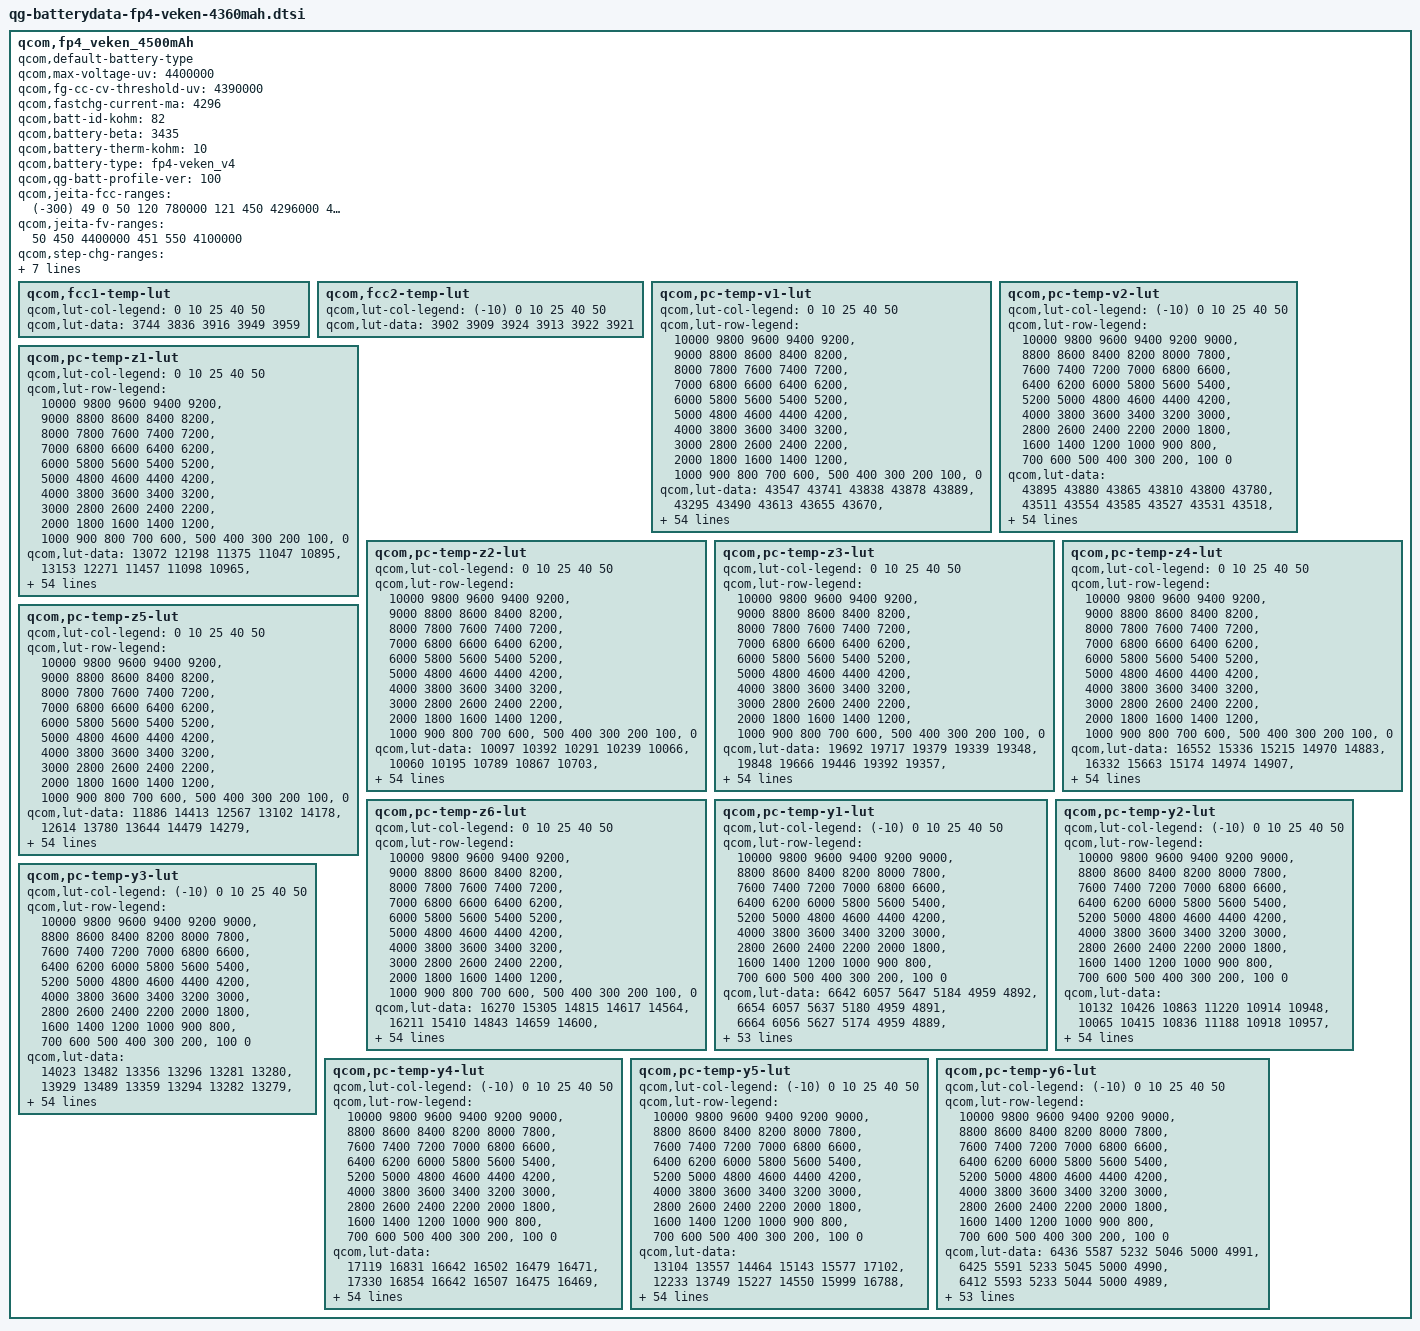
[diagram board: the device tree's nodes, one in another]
/*
 * Copyright (c) 2018, The Linux Foundation. All rights reserved.
 *
 * This program is free software; you can redistribute it and/or modify
 * it under the terms of the GNU General Public License version 2 and
 * only version 2 as published by the Free Software Foundation.
 *
 * This program is distributed in the hope that it will be useful,
 * but WITHOUT ANY WARRANTY; without even the implied warranty of
 * MERCHANTABILITY or FITNESS FOR A PARTICULAR PURPOSE.  See the
 * GNU General Public License for more details.
 */

qcom,fp4_veken_4500mAh {
	/* 4251176_TCL_T1Pro_Veken_4500mAH_PM6150_averaged_MasterSlave_Nov29th2019 */
	qcom,default-battery-type;
	qcom,max-voltage-uv = <4400000>;
	qcom,fg-cc-cv-threshold-uv = <4390000>;
	qcom,fastchg-current-ma = <4296>;//change to 1.1c
	qcom,batt-id-kohm = <82>;
	qcom,battery-beta = <3435>;
	qcom,battery-therm-kohm = <10>;
	qcom,battery-type = "fp4-veken_v4";
	qcom,qg-batt-profile-ver = <100>;

/*zxzadd if change below value  need change the value temperature define in driver
smblib_get_prop_batt_health 
#define JEITA_HARD_COLD_TEMP (0)
#define JEITA_SOFT_COLD_TEMP (100)
#define JEITA_SOFT_HOT_TEMP (450)
#define JEITA_HARD_HOT_TEMP (600)
*/
	qcom,jeita-fcc-ranges = <(-300) 49   0
							50 120   780000
							121 450  4296000
							451 550  1950000
							551 600  0>;

	qcom,jeita-fv-ranges = <50   450   4400000
							451 550   4100000>;

	qcom,step-chg-ranges = <2800000  4250000  4296000
							4250001  4400000  1950000>;

	qcom,ocv-based-step-chg;

/*zxz add comment below value need check */
/*zxz add should notice that below jeitavalue is not work, them is not set in driver, defined 'qcom,sw-jeita-enable' in dtsi ,but smblib_notifier_call
function add "if ((!chg->sw_jeita_enabled)" so not do "jeita_update_work" .
jeita value is set in amss_smxx50/BOOT.XF.3.3/boot_images/QcomPkg/SocPkg/BitraPkg/Settings/Charger/QcomChargerConfig_VbattTh_fp4.cfg

*/
	/* COOL = 10 DegC, WARM = 45 DegC */
	qcom,jeita-soft-thresholds = <0x2aee 0xfb3>;
	/* COLD = 0 DegC, HOT = 60 DegC */
	qcom,jeita-hard-thresholds = <0x3733 0xa2c>;
	/* COOL hys = 13 DegC, WARM hys = 42 DegC */
	qcom,jeita-soft-hys-thresholds = <0x279a 0x1124>;

	qcom,jeita-soft-fcc-ua = <1950000 1950000>;
	qcom,jeita-soft-fv-uv = <4100000 4100000>;


	qcom,fcc1-temp-lut {
		qcom,lut-col-legend = <0 10 25 40 50>;
		qcom,lut-data = <3744 3836 3916 3949 3959>;
	};

	qcom,fcc2-temp-lut {
		qcom,lut-col-legend = <(-10) 0 10 25 40 50>;
		qcom,lut-data = <3902 3909 3924 3913 3922 3921>;
	};

	qcom,pc-temp-v1-lut {
		qcom,lut-col-legend = <0 10 25 40 50>;
		qcom,lut-row-legend = <10000 9800 9600 9400 9200>,
			<9000 8800 8600 8400 8200>,
			<8000 7800 7600 7400 7200>,
			<7000 6800 6600 6400 6200>,
			<6000 5800 5600 5400 5200>,
			<5000 4800 4600 4400 4200>,
			<4000 3800 3600 3400 3200>,
			<3000 2800 2600 2400 2200>,
			<2000 1800 1600 1400 1200>,
			<1000 900 800 700 600>,
			<500 400 300 200 100>,
			<0>;
		qcom,lut-data = <43547 43741 43838 43878 43889>,
			<43295 43490 43613 43655 43670>,
			<43050 43248 43383 43427 43440>,
			<42810 43012 43144 43197 43212>,
			<42578 42778 42901 42964 42985>,
			<42352 42543 42663 42729 42756>,
			<42130 42311 42432 42497 42523>,
			<41913 42086 42202 42264 42288>,
			<41701 41865 41972 42034 42057>,
			<41493 41648 41743 41805 41828>,
			<41290 41432 41520 41578 41602>,
			<41096 41222 41303 41358 41381>,
			<40916 41031 41091 41141 41163>,
			<40725 40857 40889 40934 40953>,
			<40489 40671 40692 40734 40749>,
			<40233 40440 40494 40537 40551>,
			<40030 40197 40287 40336 40358>,
			<39878 40011 40093 40139 40172>,
			<39745 39867 39932 39965 39996>,
			<39614 39729 39790 39817 39837>,
			<39490 39582 39629 39654 39668>,
			<39364 39431 39427 39435 39456>,
			<39234 39250 39214 39196 39226>,
			<39101 38993 39010 39008 39036>,
			<38958 38765 38808 38853 38879>,
			<38791 38651 38665 38724 38742>,
			<38642 38577 38578 38619 38625>,
			<38546 38512 38508 38527 38523>,
			<38474 38452 38432 38437 38428>,
			<38417 38398 38359 38346 38339>,
			<38373 38346 38291 38264 38259>,
			<38337 38296 38226 38192 38185>,
			<38301 38250 38168 38128 38118>,
			<38267 38206 38116 38071 38056>,
			<38236 38165 38070 38021 38002>,
			<38206 38128 38028 37973 37946>,
			<38177 38098 37994 37925 37886>,
			<38138 38061 37957 37876 37822>,
			<38076 37999 37899 37810 37747>,
			<37995 37907 37812 37724 37659>,
			<37898 37807 37713 37626 37559>,
			<37773 37693 37605 37517 37449>,
			<37632 37561 37479 37391 37321>,
			<37474 37401 37318 37231 37161>,
			<37333 37253 37171 37090 37024>,
			<37240 37160 37074 36995 36937>,
			<37217 37136 37052 36970 36914>,
			<37195 37117 37035 36956 36897>,
			<37169 37102 37019 36938 36879>,
			<37122 37068 36985 36895 36827>,
			<36943 36874 36782 36669 36577>,
			<36509 36445 36359 36241 36147>,
			<35943 35888 35803 35679 35583>,
			<35182 35126 35038 34914 34818>,
			<33980 33929 33854 33733 33636>,
			<30000 30000 30000 30000 30000>;
	};

	qcom,pc-temp-v2-lut {
		qcom,lut-col-legend = <(-10) 0 10 25 40 50>;
		qcom,lut-row-legend = <10000 9800 9600 9400 9200 9000>,
			<8800 8600 8400 8200 8000 7800>,
			<7600 7400 7200 7000 6800 6600>,
			<6400 6200 6000 5800 5600 5400>,
			<5200 5000 4800 4600 4400 4200>,
			<4000 3800 3600 3400 3200 3000>,
			<2800 2600 2400 2200 2000 1800>,
			<1600 1400 1200 1000 900 800>,
			<700 600 500 400 300 200>,
			<100 0>;
		qcom,lut-data = <43895 43880 43865 43810 43800 43780>,
			<43511 43554 43585 43527 43531 43518>,
			<43163 43251 43318 43260 43272 43264>,
			<42853 42975 43063 43007 43025 43020>,
			<42574 42725 42822 42771 42790 42786>,
			<42328 42484 42585 42539 42558 42555>,
			<42128 42243 42348 42306 42325 42322>,
			<41947 42007 42113 42075 42093 42091>,
			<41721 41776 41885 41847 41865 41864>,
			<41415 41548 41660 41623 41639 41640>,
			<41171 41332 41442 41401 41416 41418>,
			<41071 41140 41229 41184 41196 41200>,
			<41004 40961 41022 40969 40980 40984>,
			<40846 40769 40819 40763 40774 40778>,
			<40354 40568 40619 40562 40576 40576>,
			<39851 40346 40417 40366 40383 40381>,
			<39605 40059 40208 40166 40187 40193>,
			<39428 39735 39994 39968 39994 40012>,
			<39255 39498 39777 39793 39818 39838>,
			<39085 39340 39552 39647 39666 39679>,
			<38919 39196 39337 39492 39504 39509>,
			<38743 39029 39141 39274 39288 39291>,
			<38565 38856 38960 39017 39044 39049>,
			<38430 38702 38801 38817 38850 38857>,
			<38335 38570 38661 38668 38698 38706>,
			<38258 38445 38535 38543 38568 38577>,
			<38188 38310 38421 38434 38455 38463>,
			<38126 38172 38318 38338 38355 38362>,
			<38069 38076 38224 38248 38264 38268>,
			<38014 38014 38139 38161 38180 38180>,
			<37963 37966 38059 38082 38104 38101>,
			<37914 37923 37979 38011 38035 38030>,
			<37867 37886 37904 37948 37972 37966>,
			<37818 37850 37846 37888 37907 37898>,
			<37767 37816 37805 37834 37841 37826>,
			<37713 37780 37768 37779 37770 37747>,
			<37655 37733 37729 37718 37683 37648>,
			<37593 37673 37689 37651 37581 37532>,
			<37525 37607 37640 37580 37490 37430>,
			<37450 37537 37574 37507 37413 37349>,
			<37370 37459 37494 37428 37336 37269>,
			<37287 37365 37393 37333 37241 37174>,
			<37199 37249 37267 37217 37130 37065>,
			<37116 37120 37124 37079 36995 36930>,
			<37037 36983 36991 36952 36881 36817>,
			<36946 36880 36911 36895 36832 36773>,
			<36895 36845 36888 36881 36820 36764>,
			<36841 36810 36867 36864 36804 36748>,
			<36776 36769 36837 36843 36783 36724>,
			<36688 36698 36776 36790 36718 36649>,
			<36506 36521 36579 36592 36485 36381>,
			<36138 36111 36133 36140 36015 35908>,
			<35550 35513 35515 35555 35413 35297>,
			<34710 34679 34667 34771 34602 34476>,
			<33331 33366 33473 33598 33431 33279>,
			<30369 29555 29368 29464 29626 29624>;
	};

	qcom,pc-temp-z1-lut {
		qcom,lut-col-legend = <0 10 25 40 50>;
		qcom,lut-row-legend = <10000 9800 9600 9400 9200>,
			<9000 8800 8600 8400 8200>,
			<8000 7800 7600 7400 7200>,
			<7000 6800 6600 6400 6200>,
			<6000 5800 5600 5400 5200>,
			<5000 4800 4600 4400 4200>,
			<4000 3800 3600 3400 3200>,
			<3000 2800 2600 2400 2200>,
			<2000 1800 1600 1400 1200>,
			<1000 900 800 700 600>,
			<500 400 300 200 100>,
			<0>;
		qcom,lut-data = <13072 12198 11375 11047 10895>,
			<13153 12271 11457 11098 10965>,
			<13199 12267 11500 11129 11004>,
			<13200 12251 11497 11134 11014>,
			<13156 12242 11488 11131 11016>,
			<13116 12236 11479 11129 11017>,
			<13112 12229 11469 11127 11017>,
			<13110 12216 11460 11126 11017>,
			<13107 12194 11456 11124 11017>,
			<13083 12184 11453 11122 11016>,
			<13053 12183 11452 11121 11014>,
			<13041 12183 11452 11120 11014>,
			<13034 12174 11452 11120 11014>,
			<13027 12141 11449 11120 11013>,
			<13009 12115 11445 11118 11012>,
			<12977 12105 11442 11116 11011>,
			<12946 12097 11439 11116 11012>,
			<12910 12096 11438 11117 11013>,
			<12882 12096 11439 11117 11015>,
			<12884 12098 11443 11117 11016>,
			<12902 12108 11447 11117 11018>,
			<12915 12124 11451 11118 11018>,
			<12914 12130 11455 11119 11018>,
			<12911 12123 11460 11121 11018>,
			<12915 12117 11465 11124 11021>,
			<12932 12120 11471 11128 11025>,
			<12949 12129 11478 11132 11027>,
			<12952 12137 11485 11136 11028>,
			<12947 12148 11491 11140 11031>,
			<12944 12158 11496 11145 11034>,
			<12943 12161 11501 11149 11037>,
			<12942 12162 11506 11152 11040>,
			<12943 12162 11511 11154 11044>,
			<12948 12165 11516 11158 11047>,
			<12954 12168 11522 11163 11049>,
			<12964 12175 11529 11167 11052>,
			<12980 12192 11537 11171 11055>,
			<12996 12207 11546 11175 11059>,
			<13016 12215 11552 11179 11061>,
			<13036 12224 11557 11183 11063>,
			<13040 12228 11562 11186 11065>,
			<13028 12234 11571 11188 11068>,
			<13030 12240 11578 11191 11070>,
			<13040 12251 11581 11194 11072>,
			<13065 12253 11590 11198 11072>,
			<13039 12240 11598 11200 11073>,
			<13034 12238 11600 11199 11075>,
			<13039 12234 11597 11200 11074>,
			<13022 12240 11604 11201 11075>,
			<13058 12240 11608 11205 11078>,
			<13080 12259 11613 11210 11080>,
			<13051 12280 11628 11214 11085>,
			<13103 12296 11638 11224 11094>,
			<13106 12313 11652 11236 11106>,
			<13106 12313 11652 11236 11106>,
			<13106 12313 11652 11236 11106>;
	};

	qcom,pc-temp-z2-lut {
		qcom,lut-col-legend = <0 10 25 40 50>;
		qcom,lut-row-legend = <10000 9800 9600 9400 9200>,
			<9000 8800 8600 8400 8200>,
			<8000 7800 7600 7400 7200>,
			<7000 6800 6600 6400 6200>,
			<6000 5800 5600 5400 5200>,
			<5000 4800 4600 4400 4200>,
			<4000 3800 3600 3400 3200>,
			<3000 2800 2600 2400 2200>,
			<2000 1800 1600 1400 1200>,
			<1000 900 800 700 600>,
			<500 400 300 200 100>,
			<0>;
		qcom,lut-data = <10097 10392 10291 10239 10066>,
			<10060 10195 10789 10867 10703>,
			<10032 10156 10993 11172 11141>,
			<10016 10132 10785 11184 11217>,
			<10005 10110 10405 11047 11107>,
			<9999 10087 10313 10871 10946>,
			<9998 10069 10406 10607 10682>,
			<9997 10060 10481 10354 10369>,
			<9996 10054 10423 10377 10346>,
			<9987 10052 10311 10646 10685>,
			<9977 10057 10284 10806 10939>,
			<9976 10067 10293 10793 10930>,
			<9980 10098 10309 10772 10906>,
			<9983 10181 10389 10773 10897>,
			<9971 10231 10533 10794 10913>,
			<9946 10213 10578 10818 10920>,
			<9939 10184 10557 10839 10908>,
			<9973 10182 10524 10851 10895>,
			<10016 10199 10468 10782 10832>,
			<10032 10216 10392 10474 10500>,
			<10040 10226 10383 10302 10279>,
			<10048 10234 10437 10453 10430>,
			<10058 10236 10485 10672 10674>,
			<10069 10225 10467 10674 10711>,
			<10080 10214 10402 10441 10525>,
			<10091 10217 10374 10283 10380>,
			<10102 10230 10387 10315 10504>,
			<10111 10243 10409 10379 10737>,
			<10121 10254 10431 10436 10773>,
			<10129 10265 10457 10501 10600>,
			<10137 10271 10467 10535 10412>,
			<10145 10275 10453 10486 10284>,
			<10154 10279 10433 10407 10182>,
			<10164 10282 10422 10390 10164>,
			<10175 10286 10413 10398 10184>,
			<10185 10290 10409 10410 10215>,
			<10196 10294 10416 10440 10266>,
			<10207 10300 10431 10489 10333>,
			<10222 10314 10452 10528 10383>,
			<10238 10334 10491 10567 10426>,
			<10255 10346 10517 10587 10451>,
			<10274 10350 10525 10584 10446>,
			<10302 10358 10531 10579 10433>,
			<10357 10391 10537 10562 10430>,
			<10714 10601 10605 10535 10428>,
			<10699 10659 10640 10492 10378>,
			<10620 10695 10622 10489 10401>,
			<10531 10734 10628 10493 10409>,
			<10481 10965 10616 10471 10415>,
			<10489 11224 10672 10555 10543>,
			<10478 10796 10786 10624 10393>,
			<10367 10862 10768 10373 10166>,
			<10160 10888 10917 10329 10109>,
			<10013 10741 10891 10265 10072>,
			<10013 10741 10891 10265 10072>,
			<10013 10741 10891 10265 10072>;
	};

	qcom,pc-temp-z3-lut {
		qcom,lut-col-legend = <0 10 25 40 50>;
		qcom,lut-row-legend = <10000 9800 9600 9400 9200>,
			<9000 8800 8600 8400 8200>,
			<8000 7800 7600 7400 7200>,
			<7000 6800 6600 6400 6200>,
			<6000 5800 5600 5400 5200>,
			<5000 4800 4600 4400 4200>,
			<4000 3800 3600 3400 3200>,
			<3000 2800 2600 2400 2200>,
			<2000 1800 1600 1400 1200>,
			<1000 900 800 700 600>,
			<500 400 300 200 100>,
			<0>;
		qcom,lut-data = <19692 19717 19379 19339 19348>,
			<19848 19666 19446 19392 19357>,
			<19960 19698 19494 19422 19393>,
			<19998 19730 19519 19447 19415>,
			<20015 19742 19538 19470 19432>,
			<20022 19744 19550 19481 19441>,
			<20017 19744 19559 19465 19434>,
			<20003 19741 19562 19442 19420>,
			<19995 19731 19548 19438 19417>,
			<19994 19724 19522 19448 19427>,
			<19992 19716 19505 19453 19433>,
			<19983 19707 19490 19445 19428>,
			<19959 19700 19480 19435 19417>,
			<19942 19680 19486 19429 19410>,
			<19963 19668 19500 19425 19405>,
			<20005 19662 19504 19421 19399>,
			<20017 19651 19497 19417 19393>,
			<19975 19642 19487 19414 19384>,
			<19925 19630 19473 19404 19374>,
			<19909 19621 19454 19381 19359>,
			<19902 19623 19449 19367 19349>,
			<19898 19630 19464 19380 19357>,
			<19897 19638 19481 19401 19371>,
			<19896 19653 19479 19401 19372>,
			<19896 19665 19470 19374 19346>,
			<19903 19662 19460 19354 19327>,
			<19909 19651 19447 19352 19348>,
			<19907 19641 19437 19351 19389>,
			<19897 19633 19439 19358 19401>,
			<19885 19626 19448 19394 19403>,
			<19871 19625 19458 19418 19403>,
			<19856 19626 19471 19417 19398>,
			<19844 19626 19482 19415 19387>,
			<19832 19628 19483 19411 19378>,
			<19821 19630 19480 19403 19370>,
			<19810 19629 19476 19394 19364>,
			<19798 19622 19469 19387 19361>,
			<19789 19615 19460 19381 19359>,
			<19783 19612 19455 19377 19357>,
			<19777 19609 19452 19374 19355>,
			<19768 19605 19448 19372 19354>,
			<19754 19597 19444 19371 19356>,
			<19735 19586 19440 19371 19359>,
			<19702 19570 19433 19369 19360>,
			<19564 19516 19417 19360 19358>,
			<19491 19495 19412 19356 19349>,
			<19391 19477 19402 19352 19336>,
			<19331 19456 19401 19343 19335>,
			<19326 19385 19393 19343 19329>,
			<19323 19329 19371 19335 19323>,
			<19322 19453 19372 19332 19344>,
			<19330 19427 19363 19359 19359>,
			<19335 19329 19330 19360 19365>,
			<19340 19314 19322 19355 19361>,
			<19340 19314 19322 19355 19361>,
			<19340 19314 19322 19355 19361>;
	};

	qcom,pc-temp-z4-lut {
		qcom,lut-col-legend = <0 10 25 40 50>;
		qcom,lut-row-legend = <10000 9800 9600 9400 9200>,
			<9000 8800 8600 8400 8200>,
			<8000 7800 7600 7400 7200>,
			<7000 6800 6600 6400 6200>,
			<6000 5800 5600 5400 5200>,
			<5000 4800 4600 4400 4200>,
			<4000 3800 3600 3400 3200>,
			<3000 2800 2600 2400 2200>,
			<2000 1800 1600 1400 1200>,
			<1000 900 800 700 600>,
			<500 400 300 200 100>,
			<0>;
		qcom,lut-data = <16552 15336 15215 14970 14883>,
			<16332 15663 15174 14974 14907>,
			<16126 15572 15126 14943 14882>,
			<15932 15376 15066 14904 14855>,
			<15743 15232 14998 14849 14817>,
			<15582 15136 14936 14813 14787>,
			<15463 15059 14871 14803 14776>,
			<15366 15000 14828 14795 14766>,
			<15284 14953 14814 14782 14756>,
			<15213 14917 14804 14749 14727>,
			<15152 14889 14797 14727 14705>,
			<15102 14865 14793 14722 14702>,
			<15059 14838 14787 14717 14699>,
			<15021 14802 14765 14710 14695>,
			<14985 14784 14728 14699 14688>,
			<14952 14802 14714 14689 14682>,
			<14929 14829 14711 14683 14679>,
			<14913 14831 14709 14677 14677>,
			<14899 14804 14705 14676 14675>,
			<14878 14776 14701 14685 14680>,
			<14849 14764 14705 14698 14690>,
			<14830 14755 14724 14724 14713>,
			<14823 14759 14755 14766 14756>,
			<14819 14837 14803 14809 14796>,
			<14822 14915 14873 14858 14842>,
			<14858 14918 14899 14883 14868>,
			<14892 14908 14892 14876 14839>,
			<14895 14896 14879 14859 14779>,
			<14894 14881 14861 14831 14744>,
			<14893 14864 14833 14778 14724>,
			<14884 14847 14805 14737 14712>,
			<14868 14828 14775 14720 14705>,
			<14855 14810 14750 14709 14701>,
			<14843 14794 14739 14706 14698>,
			<14831 14780 14732 14705 14696>,
			<14820 14769 14730 14704 14694>,
			<14810 14761 14729 14707 14697>,
			<14801 14757 14729 14713 14704>,
			<14790 14758 14732 14720 14711>,
			<14783 14761 14745 14733 14723>,
			<14782 14761 14752 14741 14729>,
			<14783 14754 14742 14732 14719>,
			<14782 14748 14732 14723 14708>,
			<14776 14744 14731 14725 14710>,
			<14774 14720 14716 14718 14700>,
			<14833 14712 14697 14700 14689>,
			<14938 14718 14694 14694 14689>,
			<14997 14732 14677 14681 14671>,
			<14996 14799 14669 14658 14652>,
			<14990 14855 14687 14659 14647>,
			<14987 14723 14709 14696 14665>,
			<15004 14767 14735 14680 14660>,
			<15009 14883 14772 14679 14655>,
			<15018 14903 14783 14687 14661>,
			<15018 14903 14783 14687 14661>,
			<15018 14903 14783 14687 14661>;
	};

	qcom,pc-temp-z5-lut {
		qcom,lut-col-legend = <0 10 25 40 50>;
		qcom,lut-row-legend = <10000 9800 9600 9400 9200>,
			<9000 8800 8600 8400 8200>,
			<8000 7800 7600 7400 7200>,
			<7000 6800 6600 6400 6200>,
			<6000 5800 5600 5400 5200>,
			<5000 4800 4600 4400 4200>,
			<4000 3800 3600 3400 3200>,
			<3000 2800 2600 2400 2200>,
			<2000 1800 1600 1400 1200>,
			<1000 900 800 700 600>,
			<500 400 300 200 100>,
			<0>;
		qcom,lut-data = <11886 14413 12567 13102 14178>,
			<12614 13780 13644 14479 14279>,
			<13204 14265 14624 15634 16088>,
			<13607 14843 15494 16974 17343>,
			<13900 15368 16345 18793 18701>,
			<14135 15882 17208 19693 19560>,
			<14338 16345 18357 18973 19423>,
			<14529 16749 19093 17953 19227>,
			<14759 17188 19044 18480 19855>,
			<15214 17541 18856 21544 23476>,
			<15659 18062 18677 23352 26139>,
			<15766 18631 18349 23071 25691>,
			<15786 19177 18101 22663 24784>,
			<15818 20344 19895 22874 24720>,
			<17557 20981 23876 24323 26144>,
			<21016 20322 25137 25835 27203>,
			<22203 19430 24533 27136 26780>,
			<21184 19541 23684 28285 25703>,
			<20069 20118 23016 27744 24271>,
			<20255 21038 22919 23542 21923>,
			<21764 23532 24295 21313 20779>,
			<23804 28090 32731 26724 23517>,
			<26533 32520 41002 34677 27989>,
			<30194 37714 39409 34519 28103>,
			<34261 41364 32041 24669 20795>,
			<39901 39609 26133 17194 15196>,
			<43976 33334 22016 15796 15983>,
			<43531 28780 19356 15011 17918>,
			<40937 26400 19188 15359 19582>,
			<38199 24888 19413 18225 21177>,
			<35616 24801 19831 21410 22344>,
			<33158 25294 22413 23899 22861>,
			<31585 26003 26202 26110 23226>,
			<30517 27885 29171 27448 23749>,
			<29680 30346 32046 28444 24523>,
			<28861 31082 33178 28875 25138>,
			<28088 31087 32459 28333 25470>,
			<27851 31026 31138 27139 25695>,
			<29032 31420 29725 25716 25308>,
			<30503 32217 27880 23446 22685>,
			<30384 32267 26244 21667 20847>,
			<28748 30519 25091 20970 20928>,
			<27814 28564 24014 20404 21047>,
			<26873 26828 22620 19641 20984>,
			<22035 27109 23042 18982 20817>,
			<18173 25404 24156 18997 19077>,
			<13919 21365 21787 18653 17041>,
			<12110 19251 22544 18066 18007>,
			<12039 15544 21621 20382 19528>,
			<12053 12864 17589 19192 19704>,
			<12124 19269 16872 15338 18983>,
			<12051 15940 14845 16984 19612>,
			<11973 12316 12947 16550 20090>,
			<11867 11920 12520 15346 17888>,
			<11867 11920 12520 15346 17888>,
			<11867 11920 12520 15346 17888>;
	};

	qcom,pc-temp-z6-lut {
		qcom,lut-col-legend = <0 10 25 40 50>;
		qcom,lut-row-legend = <10000 9800 9600 9400 9200>,
			<9000 8800 8600 8400 8200>,
			<8000 7800 7600 7400 7200>,
			<7000 6800 6600 6400 6200>,
			<6000 5800 5600 5400 5200>,
			<5000 4800 4600 4400 4200>,
			<4000 3800 3600 3400 3200>,
			<3000 2800 2600 2400 2200>,
			<2000 1800 1600 1400 1200>,
			<1000 900 800 700 600>,
			<500 400 300 200 100>,
			<0>;
		qcom,lut-data = <16270 15305 14815 14617 14564>,
			<16211 15410 14843 14659 14600>,
			<16142 15378 14853 14670 14613>,
			<16062 15296 14844 14670 14615>,
			<15962 15229 14819 14661 14609>,
			<15866 15178 14796 14649 14600>,
			<15791 15134 14775 14635 14591>,
			<15725 15097 14755 14621 14580>,
			<15672 15065 14736 14610 14571>,
			<15630 15040 14719 14602 14565>,
			<15592 15022 14706 14595 14560>,
			<15549 15006 14697 14588 14554>,
			<15498 14982 14689 14581 14548>,
			<15463 14950 14681 14574 14542>,
			<15451 14934 14674 14566 14535>,
			<15445 14935 14667 14559 14529>,
			<15432 14937 14661 14554 14523>,
			<15399 14934 14655 14550 14518>,
			<15364 14915 14647 14544 14513>,
			<15345 14900 14636 14536 14507>,
			<15331 14900 14633 14531 14503>,
			<15324 14901 14649 14549 14517>,
			<15324 14905 14673 14581 14545>,
			<15323 14948 14695 14596 14559>,
			<15326 14989 14719 14603 14566>,
			<15347 14990 14728 14606 14569>,
			<15367 14982 14720 14602 14567>,
			<15367 14974 14710 14595 14563>,
			<15364 14965 14703 14589 14558>,
			<15359 14956 14697 14585 14552>,
			<15349 14948 14692 14581 14546>,
			<15337 14942 14687 14575 14540>,
			<15327 14937 14683 14569 14533>,
			<15318 14933 14680 14564 14528>,
			<15311 14930 14676 14560 14522>,
			<15303 14927 14674 14556 14519>,
			<15297 14923 14670 14555 14519>,
			<15294 14920 14667 14554 14520>,
			<15295 14923 14668 14554 14521>,
			<15296 14927 14673 14558 14525>,
			<15297 14929 14675 14561 14528>,
			<15299 14926 14671 14557 14525>,
			<15299 14923 14665 14554 14522>,
			<15291 14917 14663 14554 14523>,
			<15236 14888 14650 14547 14518>,
			<15224 14877 14641 14537 14508>,
			<15217 14870 14635 14532 14503>,
			<15212 14866 14627 14522 14493>,
			<15211 14860 14620 14512 14482>,
			<15213 14859 14618 14508 14476>,
			<15220 14871 14630 14524 14497>,
			<15239 14883 14640 14533 14505>,
			<15255 14891 14642 14536 14508>,
			<15282 14904 14647 14540 14512>,
			<15282 14904 14647 14540 14512>,
			<15282 14904 14647 14540 14512>;
	};

	qcom,pc-temp-y1-lut {
		qcom,lut-col-legend = <(-10) 0 10 25 40 50>;
		qcom,lut-row-legend = <10000 9800 9600 9400 9200 9000>,
			<8800 8600 8400 8200 8000 7800>,
			<7600 7400 7200 7000 6800 6600>,
			<6400 6200 6000 5800 5600 5400>,
			<5200 5000 4800 4600 4400 4200>,
			<4000 3800 3600 3400 3200 3000>,
			<2800 2600 2400 2200 2000 1800>,
			<1600 1400 1200 1000 900 800>,
			<700 600 500 400 300 200>,
			<100 0>;
		qcom,lut-data = <6642 6057 5647 5184 4959 4892>,
			<6654 6057 5637 5180 4959 4891>,
			<6664 6056 5627 5174 4959 4889>,
			<6673 6053 5616 5168 4957 4887>,
			<6680 6051 5608 5163 4956 4886>,
			<6684 6050 5601 5160 4954 4885>,
			<6676 6050 5596 5159 4952 4884>,
			<6661 6049 5592 5158 4950 4884>,
			<6656 6048 5586 5156 4948 4883>,
			<6652 6041 5577 5153 4945 4882>,
			<6650 6034 5571 5149 4944 4881>,
			<6665 6024 5568 5147 4944 4880>,
			<6695 6013 5566 5146 4944 4879>,
			<6702 6012 5562 5145 4944 4879>,
			<6688 6029 5556 5145 4941 4879>,
			<6676 6044 5552 5144 4939 4879>,
			<6680 6046 5556 5145 4941 4879>,
			<6691 6047 5564 5145 4943 4880>,
			<6695 6049 5567 5146 4944 4879>,
			<6694 6051 5565 5148 4943 4878>,
			<6693 6052 5563 5150 4943 4877>,
			<6689 6051 5561 5152 4943 4878>,
			<6679 6046 5559 5154 4945 4880>,
			<6668 6043 5560 5156 4946 4882>,
			<6652 6048 5569 5161 4948 4883>,
			<6639 6052 5577 5166 4951 4883>,
			<6636 6048 5577 5170 4953 4885>,
			<6639 6037 5577 5174 4955 4888>,
			<6638 6033 5578 5178 4957 4890>,
			<6630 6035 5585 5182 4960 4891>,
			<6621 6038 5590 5187 4962 4893>,
			<6617 6035 5589 5192 4965 4895>,
			<6615 6029 5584 5198 4968 4898>,
			<6613 6028 5584 5203 4971 4900>,
			<6614 6033 5587 5208 4976 4901>,
			<6614 6039 5590 5212 4980 4903>,
			<6608 6038 5590 5214 4981 4904>,
			<6593 6037 5590 5217 4981 4907>,
			<6584 6035 5593 5219 4982 4908>,
			<6593 6027 5607 5222 4983 4909>,
			<6607 6017 5620 5225 4984 4910>,
			<6610 6012 5623 5229 4985 4911>,
			<6608 6005 5621 5233 4986 4911>,
			<6596 5999 5621 5239 4988 4912>,
			<6565 5999 5625 5248 4992 4914>,
			<6605 6021 5632 5253 4996 4917>,
			<6605 6033 5628 5252 4996 4919>,
			<6619 6044 5644 5251 4996 4919>,
			<6619 6049 5641 5257 4996 4918>,
			<6595 6023 5643 5254 4997 4918>,
			<6619 6016 5641 5266 4996 4919>,
			<6652 6020 5649 5267 5001 4922>,
			<6670 6044 5660 5281 5007 4926>,
			<6745 6053 5663 5299 5015 4934>,
			<6745 6053 5663 5299 5015 4934>,
			<6745 6053 5663 5299 5015 4934>;
	};

	qcom,pc-temp-y2-lut {
		qcom,lut-col-legend = <(-10) 0 10 25 40 50>;
		qcom,lut-row-legend = <10000 9800 9600 9400 9200 9000>,
			<8800 8600 8400 8200 8000 7800>,
			<7600 7400 7200 7000 6800 6600>,
			<6400 6200 6000 5800 5600 5400>,
			<5200 5000 4800 4600 4400 4200>,
			<4000 3800 3600 3400 3200 3000>,
			<2800 2600 2400 2200 2000 1800>,
			<1600 1400 1200 1000 900 800>,
			<700 600 500 400 300 200>,
			<100 0>;
		qcom,lut-data = <10132 10426 10863 11220 10914 10948>,
			<10065 10415 10836 11188 10918 10957>,
			<10035 10412 10808 11137 10916 10958>,
			<10034 10413 10780 11080 10911 10955>,
			<10053 10419 10757 11030 10902 10947>,
			<10083 10426 10741 11001 10891 10937>,
			<10138 10440 10729 10987 10869 10906>,
			<10219 10457 10721 10974 10844 10855>,
			<10285 10457 10720 10975 10848 10816>,
			<10348 10433 10722 10979 10912 10779>,
			<10387 10414 10724 10982 10959 10760>,
			<10390 10514 10725 10975 10935 10781>,
			<10385 10707 10727 10961 10890 10820>,
			<10406 10756 10740 10959 10880 10825>,
			<10547 10713 10812 10971 10902 10795>,
			<10666 10677 10876 10992 10933 10771>,
			<10427 10687 10896 11040 10964 10825>,
			<9874 10718 10908 11117 11004 10946>,
			<9680 10749 10918 11170 11064 11029>,
			<9676 10783 10928 11210 11186 11092>,
			<9674 10819 10939 11233 11271 11126>,
			<9671 10862 10959 11210 11231 11118>,
			<9669 10907 10989 11155 11142 11096>,
			<9667 10922 11017 11138 11102 11081>,
			<9666 10917 11043 11163 11086 11059>,
			<9665 10913 11068 11196 11079 11046>,
			<9664 10935 11094 11221 11102 11064>,
			<9663 10989 11118 11244 11165 11104>,
			<9662 11009 11125 11266 11220 11135>,
			<9661 10985 11125 11287 11265 11165>,
			<9661 10949 11125 11305 11309 11192>,
			<9660 10916 11131 11319 11360 11215>,
			<9659 10877 11144 11334 11413 11243>,
			<9659 10835 11147 11340 11440 11268>,
			<9658 10799 11125 11333 11430 11304>,
			<9658 10749 11096 11321 11400 11333>,
			<9658 10529 11074 11310 11335 11305>,
			<9658 9982 11053 11291 11225 11212>,
			<9657 9704 11028 11275 11179 11170>,
			<9657 9689 10997 11264 11187 11152>,
			<9657 9680 10960 11251 11202 11128>,
			<9656 9673 10915 11228 11195 11112>,
			<9656 9667 10863 11194 11166 11101>,
			<9656 9664 10807 11176 11137 11085>,
			<9656 9662 10737 11153 11087 11025>,
			<9656 9660 10662 11060 11044 10878>,
			<9656 9660 10652 11077 11021 10822>,
			<9655 9659 10623 11069 10993 10835>,
			<9655 9658 10591 11075 11004 10850>,
			<9655 9657 10575 11052 11010 10876>,
			<9654 9656 10516 11046 10971 10829>,
			<9654 9656 10433 10998 10904 10745>,
			<9652 9654 10343 10919 10826 10684>,
			<9650 9653 10081 10860 10774 10611>,
			<9650 9653 10081 10860 10774 10611>,
			<9650 9653 10081 10860 10774 10611>;
	};

	qcom,pc-temp-y3-lut {
		qcom,lut-col-legend = <(-10) 0 10 25 40 50>;
		qcom,lut-row-legend = <10000 9800 9600 9400 9200 9000>,
			<8800 8600 8400 8200 8000 7800>,
			<7600 7400 7200 7000 6800 6600>,
			<6400 6200 6000 5800 5600 5400>,
			<5200 5000 4800 4600 4400 4200>,
			<4000 3800 3600 3400 3200 3000>,
			<2800 2600 2400 2200 2000 1800>,
			<1600 1400 1200 1000 900 800>,
			<700 600 500 400 300 200>,
			<100 0>;
		qcom,lut-data = <14023 13482 13356 13296 13281 13280>,
			<13929 13489 13359 13294 13282 13279>,
			<13869 13495 13362 13293 13283 13278>,
			<13836 13499 13365 13293 13284 13278>,
			<13822 13502 13368 13294 13285 13278>,
			<13819 13503 13370 13295 13286 13278>,
			<13845 13501 13370 13297 13288 13279>,
			<13891 13498 13370 13300 13289 13280>,
			<13877 13499 13370 13302 13290 13281>,
			<13690 13515 13372 13306 13291 13285>,
			<13543 13527 13373 13308 13291 13288>,
			<13558 13505 13372 13308 13291 13289>,
			<13595 13463 13371 13307 13292 13290>,
			<13604 13451 13370 13308 13292 13290>,
			<13589 13457 13370 13312 13297 13290>,
			<13567 13461 13370 13316 13301 13290>,
			<13541 13456 13370 13314 13299 13291>,
			<13512 13442 13371 13310 13295 13294>,
			<13504 13433 13370 13309 13294 13295>,
			<13510 13428 13364 13313 13296 13295>,
			<13516 13423 13357 13317 13297 13295>,
			<13508 13415 13352 13314 13295 13291>,
			<13486 13404 13348 13306 13289 13282>,
			<13477 13396 13344 13300 13285 13280>,
			<13483 13390 13341 13297 13283 13280>,
			<13494 13383 13338 13294 13282 13280>,
			<13510 13370 13336 13296 13282 13280>,
			<13535 13351 13334 13298 13282 13281>,
			<13561 13343 13334 13299 13282 13281>,
			<13588 13343 13333 13298 13282 13279>,
			<13618 13345 13333 13297 13283 13278>,
			<13654 13350 13331 13297 13283 13278>,
			<13698 13359 13329 13299 13284 13279>,
			<13742 13368 13328 13299 13285 13279>,
			<13782 13373 13330 13300 13285 13280>,
			<13823 13379 13333 13300 13285 13280>,
			<13866 13387 13335 13300 13284 13280>,
			<13913 13396 13338 13299 13282 13278>,
			<13963 13407 13340 13298 13281 13278>,
			<14018 13421 13343 13297 13281 13278>,
			<14074 13439 13344 13297 13282 13279>,
			<14124 13462 13343 13298 13282 13281>,
			<14168 13493 13341 13298 13283 13282>,
			<14222 13537 13342 13298 13283 13280>,
			<14289 13600 13346 13299 13282 13277>,
			<14361 13667 13347 13305 13287 13283>,
			<14301 13653 13348 13305 13288 13288>,
			<14362 13714 13355 13305 13293 13290>,
			<14443 13786 13364 13314 13299 13293>,
			<14546 13863 13373 13320 13300 13293>,
			<14653 13942 13376 13314 13295 13289>,
			<14795 14061 13379 13310 13293 13290>,
			<15283 14266 13392 13321 13296 13292>,
			<16203 14597 13423 13330 13303 13297>,
			<16203 14597 13423 13330 13303 13297>,
			<16203 14597 13423 13330 13303 13297>;
	};

	qcom,pc-temp-y4-lut {
		qcom,lut-col-legend = <(-10) 0 10 25 40 50>;
		qcom,lut-row-legend = <10000 9800 9600 9400 9200 9000>,
			<8800 8600 8400 8200 8000 7800>,
			<7600 7400 7200 7000 6800 6600>,
			<6400 6200 6000 5800 5600 5400>,
			<5200 5000 4800 4600 4400 4200>,
			<4000 3800 3600 3400 3200 3000>,
			<2800 2600 2400 2200 2000 1800>,
			<1600 1400 1200 1000 900 800>,
			<700 600 500 400 300 200>,
			<100 0>;
		qcom,lut-data = <17119 16831 16642 16502 16479 16471>,
			<17330 16854 16642 16507 16475 16469>,
			<17459 16885 16642 16511 16472 16468>,
			<17527 16918 16644 16514 16471 16468>,
			<17552 16946 16645 16517 16470 16468>,
			<17556 16961 16647 16519 16470 16468>,
			<17488 16967 16648 16521 16472 16470>,
			<17367 16970 16650 16522 16474 16472>,
			<17374 16967 16654 16523 16477 16472>,
			<17656 16939 16664 16528 16481 16472>,
			<17900 16918 16677 16534 16486 16472>,
			<17945 17011 16689 16542 16493 16474>,
			<17972 17189 16704 16555 16502 16479>,
			<17930 17238 16734 16568 16508 16485>,
			<17476 17225 16806 16581 16511 16494>,
			<17080 17202 16856 16597 16515 16503>,
			<17109 17093 16853 16618 16526 16509>,
			<17208 16899 16840 16643 16546 16515>,
			<17237 16836 16816 16665 16567 16525>,
			<17166 16834 16739 16688 16597 16550>,
			<17072 16833 16663 16702 16616 16568>,
			<17000 16817 16623 16659 16590 16551>,
			<16935 16779 16594 16558 16531 16513>,
			<16912 16749 16581 16514 16499 16490>,
			<16910 16729 16574 16504 16483 16476>,
			<16910 16709 16571 16499 16476 16469>,
			<16910 16682 16572 16500 16477 16470>,
			<16910 16651 16574 16503 16483 16473>,
			<16910 16640 16575 16507 16489 16478>,
			<16910 16647 16575 16515 16498 16487>,
			<16910 16655 16575 16524 16508 16499>,
			<16910 16657 16569 16533 16521 16511>,
			<16911 16660 16557 16543 16535 16523>,
			<16912 16664 16554 16548 16539 16526>,
			<16915 16674 16562 16550 16538 16526>,
			<16920 16691 16575 16551 16536 16524>,
			<16921 16721 16589 16546 16523 16513>,
			<16922 16774 16604 16529 16495 16487>,
			<16923 16806 16615 16520 16484 16477>,
			<16918 16817 16621 16519 16485 16477>,
			<16911 16823 16626 16518 16487 16478>,
			<16912 16822 16628 16519 16488 16478>,
			<16925 16812 16630 16522 16488 16477>,
			<16941 16796 16626 16520 16481 16470>,
			<16963 16780 16623 16512 16473 16462>,
			<16992 16792 16624 16514 16474 16468>,
			<16947 16792 16621 16516 16485 16476>,
			<16963 16819 16646 16538 16500 16504>,
			<16997 16855 16681 16553 16531 16542>,
			<17029 16912 16722 16576 16549 16552>,
			<17023 16950 16725 16566 16513 16494>,
			<16985 16907 16695 16532 16478 16470>,
			<17127 16908 16710 16545 16485 16475>,
			<17490 17021 16766 16585 16513 16501>,
			<17490 17021 16766 16585 16513 16501>,
			<17490 17021 16766 16585 16513 16501>;
	};

	qcom,pc-temp-y5-lut {
		qcom,lut-col-legend = <(-10) 0 10 25 40 50>;
		qcom,lut-row-legend = <10000 9800 9600 9400 9200 9000>,
			<8800 8600 8400 8200 8000 7800>,
			<7600 7400 7200 7000 6800 6600>,
			<6400 6200 6000 5800 5600 5400>,
			<5200 5000 4800 4600 4400 4200>,
			<4000 3800 3600 3400 3200 3000>,
			<2800 2600 2400 2200 2000 1800>,
			<1600 1400 1200 1000 900 800>,
			<700 600 500 400 300 200>,
			<100 0>;
		qcom,lut-data = <13104 13557 14464 15143 15577 17102>,
			<12233 13749 15227 14550 15999 16788>,
			<11833 13980 15679 14104 16264 16235>,
			<11818 14204 15894 13783 16406 15603>,
			<12104 14376 15943 13567 16458 15054>,
			<12606 14448 15898 13435 16453 14751>,
			<14595 14417 15653 13542 16328 14590>,
			<17508 14363 15251 13812 16071 14428>,
			<17741 14452 14986 13890 15800 14548>,
			<14246 15163 14714 13970 15481 15525>,
			<11482 15710 14435 13953 15120 16242>,
			<13113 14820 14079 13620 14612 16070>,
			<16467 13096 13711 13166 14094 15640>,
			<17424 12971 13638 13021 14033 15162>,
			<17063 16007 13728 12995 14425 14483>,
			<16478 18548 13904 12983 14728 14058>,
			<15219 18005 15442 13008 14278 14197>,
			<13271 16708 18172 13097 13407 14482>,
			<12680 16365 19120 13444 13207 14557>,
			<13211 17048 19330 15697 13602 14524>,
			<13719 17720 19418 17833 14250 14495>,
			<13394 17822 19293 18297 15591 14839>,
			<12429 17824 18989 18552 17433 15707>,
			<11874 17984 18743 18506 17916 16461>,
			<11659 18797 18273 17186 17566 17210>,
			<11542 19522 17834 15930 17063 17671>,
			<11536 18300 17643 16273 16491 17496>,
			<11537 14909 17549 17289 15836 16934>,
			<11541 13340 17670 17642 15534 16266>,
			<11587 13221 18509 17156 15480 15215>,
			<11654 13304 19218 16659 15547 14449>,
			<11743 13646 18846 16861 15782 14504>,
			<11939 14398 17944 17646 16225 14802>,
			<12101 15044 17612 18347 16752 15219>,
			<12205 15661 17697 19103 17578 16080>,
			<12286 16124 17832 19670 18185 16862>,
			<12339 15642 17942 19515 17994 17088>,
			<12399 13887 18038 18810 17339 17221>,
			<12429 12972 17998 18077 16793 17245>,
			<12426 12944 17779 17343 16358 16951>,
			<12400 12953 17429 16698 16013 16629>,
			<12266 12954 16652 16273 15814 16830>,
			<11903 12956 15620 15856 15720 17336>,
			<11836 12880 15525 15809 15955 16802>,
			<11909 12658 15453 16135 16259 15475>,
			<11982 12360 15095 16764 16225 15485>,
			<12118 12374 15004 16453 15435 16617>,
			<12271 12513 14970 15027 15750 15941>,
			<12298 12850 14972 16105 16518 15735>,
			<12566 12942 15092 16635 16379 15435>,
			<12659 12751 15042 15809 16193 15842>,
			<12332 12661 15278 16057 17343 18102>,
			<11224 12640 15399 18598 18544 18606>,
			<10511 11954 15095 20229 21495 21660>,
			<10511 11954 15095 20229 21495 21660>,
			<10511 11954 15095 20229 21495 21660>;
	};

	qcom,pc-temp-y6-lut {
		qcom,lut-col-legend = <(-10) 0 10 25 40 50>;
		qcom,lut-row-legend = <10000 9800 9600 9400 9200 9000>,
			<8800 8600 8400 8200 8000 7800>,
			<7600 7400 7200 7000 6800 6600>,
			<6400 6200 6000 5800 5600 5400>,
			<5200 5000 4800 4600 4400 4200>,
			<4000 3800 3600 3400 3200 3000>,
			<2800 2600 2400 2200 2000 1800>,
			<1600 1400 1200 1000 900 800>,
			<700 600 500 400 300 200>,
			<100 0>;
		qcom,lut-data = <6436 5587 5232 5046 5000 4991>,
			<6425 5591 5233 5045 5000 4990>,
			<6412 5593 5233 5044 5000 4989>,
			<6398 5594 5232 5045 5001 4989>,
			<6387 5595 5231 5045 5002 4989>,
			<6379 5595 5229 5046 5003 4990>,
			<6376 5591 5227 5048 5004 4991>,
			<6373 5583 5224 5050 5005 4992>,
			<6363 5578 5223 5052 5007 4993>,
			<6325 5574 5224 5055 5009 4996>,
			<6296 5572 5225 5058 5011 4998>,
			<6316 5580 5226 5060 5013 4999>,
			<6358 5596 5228 5063 5015 5001>,
			<6358 5601 5233 5067 5018 5003>,
			<6240 5601 5251 5074 5021 5006>,
			<6130 5600 5264 5081 5025 5008>,
			<6112 5571 5263 5086 5028 5011>,
			<6104 5511 5261 5090 5031 5014>,
			<6096 5490 5254 5096 5035 5018>,
			<6087 5488 5228 5105 5045 5025>,
			<6078 5486 5201 5111 5051 5030>,
			<6065 5478 5186 5097 5042 5022>,
			<6050 5464 5175 5062 5020 5005>,
			<6045 5457 5169 5046 5008 4996>,
			<6058 5455 5166 5041 5003 4992>,
			<6079 5452 5165 5039 5000 4990>,
			<6100 5446 5165 5040 5000 4990>,
			<6126 5436 5166 5043 5002 4991>,
			<6152 5433 5168 5046 5004 4993>,
			<6177 5447 5171 5048 5007 4995>,
			<6203 5470 5173 5051 5010 4997>,
			<6233 5492 5172 5054 5015 5001>,
			<6268 5517 5171 5058 5020 5005>,
			<6303 5544 5171 5061 5021 5007>,
			<6337 5573 5178 5064 5021 5007>,
			<6373 5603 5188 5065 5020 5007>,
			<6409 5633 5198 5063 5016 5004>,
			<6446 5664 5209 5058 5007 4996>,
			<6485 5698 5220 5056 5004 4992>,
			<6524 5738 5231 5056 5004 4993>,
			<6563 5782 5242 5056 5006 4994>,
			<6602 5828 5252 5057 5007 4995>,
			<6642 5876 5264 5060 5007 4996>,
			<6691 5933 5279 5060 5005 4993>,
			<6753 6001 5301 5061 5003 4988>,
			<6824 6078 5313 5067 5008 4995>,
			<6781 6070 5310 5068 5012 5001>,
			<6834 6130 5338 5074 5019 5011>,
			<6906 6204 5370 5086 5032 5024>,
			<6997 6285 5407 5097 5038 5027>,
			<7082 6365 5429 5091 5025 5007>,
			<7196 6462 5449 5079 5013 5001>,
			<7700 6639 5520 5094 5019 5005>,
			<8617 6974 5615 5116 5033 5019>,
			<8617 6974 5615 5116 5033 5019>,
			<8617 6974 5615 5116 5033 5019>;
	};

};
